# AM13E230x register map
Vendor: Texas Instruments; File version: Revised: 2025-12-26 17:30:06
CPU: CM33 r0p0, little endian, MPU, FPU, 4 interrupt priority bits
Registers are 32-bit, read-write, reset 0x0 unless marked. A register's access mark holds for its fields unless they carry their own. Offsets are from the block's base; [hi:lo] are bit positions; {n}, {i} and the like mark numbered series.

## ECAP0 — ECAP_REGS
Base 0x40440000
Same registers: ECAP1 0x40441000
0x00 TSCTR — Time-Stamp Counter
0x04 CTRPHS — Counter Phase Offset Value Register
{0x4+4i} CAP{i} (i=1..4) — Capture {i} Register
0x24 ECCTL0 reset 0x7F — Capture Control Register 0
  [6:0] INPUTSEL — INPUT source select
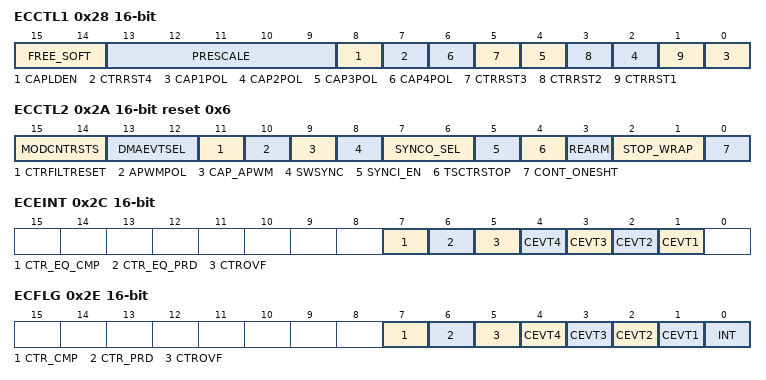
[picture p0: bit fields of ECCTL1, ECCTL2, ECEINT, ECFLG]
0x28 ECCTL1 16-bit — Capture Control Register 1
  [15:14] FREE_SOFT — Emulation mode
    0=stop_emu (TSCTR counter stops immediately on emulation suspend); 1=runs_until (TSCTR counter runs until = 0); 2=unaf_emu_sus (TSCTR counter is unaffected by emulation suspend (Run Free)); 3=unaf_emu_sus2 (TSCTR counter is unaffected by emulation suspend (Run Free))
  [13:9] PRESCALE — Event Filter prescale select
    0=div1 (Divide by 1 (i.e,. no prescale, by-pass the prescaler)); 1=div2 (Divide by 2); 2=div4 (Divide by 4); 3=div6 (Divide by 6); 4=div8 (Divide by 8); 5=div10 (Divide by 10); 30=div60 (Divide by 60); 31=div62 (Divide by 62)
  [8] CAPLDEN — Enable Loading CAP1-4 regs on a Cap Event
    0=Disable CAP1-4 register loads at capture event time; 1=Enable CAP1-4 register loads at capture event time
  [7] CTRRST4 — Counter Reset on Capture Event 4
    0=Do not reset counter on Capture Event 4 (absolute time stamp operation); 1=Reset counter after Capture Event 4 time-stamp has been captured (used in difference mode operation)
  [2n-2] CAP{n}POL (n=1..4) — Capture Event {n} Polarity select
    0=rise (Capture Event {n} triggered on a rising edge (RE)); 1=fall (Capture Event {n} triggered on a falling edge (FE))
  [5] CTRRST3 — Counter Reset on Capture Event 3
    0=Do not reset counter on Capture Event 3 (absolute time stamp); 1=Reset counter after Event 3 time-stamp has been captured (used in difference mode operation)
  [3] CTRRST2 — Counter Reset on Capture Event 2
    0=Do not reset counter on Capture Event 2 (absolute time stamp); 1=Reset counter after Event 2 time-stamp has been captured (used in difference mode operation)
  [1] CTRRST1 — Counter Reset on Capture Event 1
    0=Do not reset counter on Capture Event 1 (absolute time stamp); 1=Reset counter after Event 1 time-stamp has been captured (used in difference mode operation)
0x2A ECCTL2 16-bit reset 0x6 — Capture Control Register 2
  [15:14] MODCNTRSTS ro — modulo counter status
  [13:12] DMAEVTSEL — DMA event select
  [11] CTRFILTRESET — Reset event filter, modulus counter, and interrupt flags.
  [10] APWMPOL — APWM output polarity select
    0=high (Output is active high (Compare value defines high time)); 1=low (Output is active low (Compare value defines low time))
  [9] CAP_APWM — CAP/APWM operating mode select
    0=CAPTURE (ECAP module operates in capture mode); 1=APWM (ECAP module operates in APWM mode)
  [8] SWSYNC — SW forced counter sync
  [7:6] SYNCO_SEL — Sync-out mode
    0=SWSYNC (sync out signal is SWSYNC); 1=CTR_PRD (Select CTR = PRD event to be the sync-out signal. Note: Selection CTR = PRD is meaningful only in APWM mode); 2=DISABLE (Disable sync out signal)
  [5] SYNCI_EN — Counter sync-in select
    0=Disable sync-in option; 1=enable_counter_register (Enable counter (TSCTR) to be loaded from CTRPHS register upon either a SYNCI signal or a S/W force event.)
  [4] TSCTRSTOP — TSCNT counter stop
    0=stopped (TSCTR stopped); 1=free_running (TSCTR free-running)
  [3] REARM — One-shot re-arm
  [2:1] STOP_WRAP — Stop value for one-shot, Wrap for continuous
    {v}=StopEvent{v+1} (Stop after Capture Event {v+1} in one-shot mode #br#Wrap after Capture Event {v+1} in continuous mode.) (v=0..3)
  [0] CONT_ONESHT — Continuous or one-shot
    0=cont (Operate in continuous mode); 1=one (Operate in one-Shot mode)
0x2C ECEINT 16-bit — Capture Interrupt Enable Register
  [7] CTR_EQ_CMP — Compare Equal Interrupt Enable
    0=Disable Compare Equal as an Interrupt source; 1=Enable Compare Equal as an Interrupt source
  [6] CTR_EQ_PRD — Period Equal Interrupt Enable
    0=Disable Period Equal as an Interrupt source; 1=Enable Period Equal as an Interrupt source
  [5] CTROVF — Counter Overflow Interrupt Enable
    0=Disabled counter Overflow as an Interrupt source; 1=Enable counter Overflow as an Interrupt source
  [4] CEVT4 — Capture Event 4 Interrupt Enable
    0=Disable Capture Event 4 as an Interrupt source; 1=enab (Capture Event 4 Interrupt Enable)
  [3] CEVT3 — Capture Event 3 Interrupt Enable
    0=Disable Capture Event 3 as an Interrupt source; 1=Enable Capture Event 3 as an Interrupt source
  [2] CEVT2 — Capture Event 2 Interrupt Enable
    0=Disable Capture Event 2 as an Interrupt source; 1=Enable Capture Event 2 as an Interrupt source
  [1] CEVT1 — Capture Event 1 Interrupt Enable
    0=Disable Capture Event 1 as an Interrupt source; 1=Enable Capture Event 1 as an Interrupt source
0x2E ECFLG 16-bit — Capture Interrupt Flag Register
  [7] CTR_CMP ro — Compare Equal Interrupt Flag
  [6] CTR_PRD ro — Period Equal Interrupt Flag
  [5] CTROVF ro — Counter Overflow Interrupt Flag
  [n] CEVT{n} ro (n=1..4) — Capture Event {n} Interrupt Flag
  [0] INT ro — Global Flag
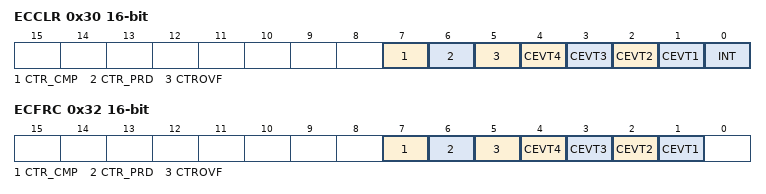
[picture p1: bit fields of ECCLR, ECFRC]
0x30 ECCLR 16-bit — Capture Interrupt Clear Register
  [7] CTR_CMP — Compare Equal Status Clear
  [6] CTR_PRD — Period Equal Status Clear
  [5] CTROVF — Counter Overflow Status Clear
  [n] CEVT{n} (n=1..4) — Capture Event {n} Status Clear
  [0] INT — ECAP Global Interrupt Status Clear
0x32 ECFRC 16-bit — Capture Interrupt Force Register
  [7] CTR_CMP — Compare Equal Force Interrupt
  [6] CTR_PRD — Period Equal Force Interrupt
  [5] CTROVF — Counter Overflow Force Interrupt
  [n] CEVT{n} (n=1..4) — Capture Event {n} Force Interrupt
0x3C ECAPSYNCINSEL reset 0x1 — SYNC source select register
  [4:0] SEL — SYNCIN source select
